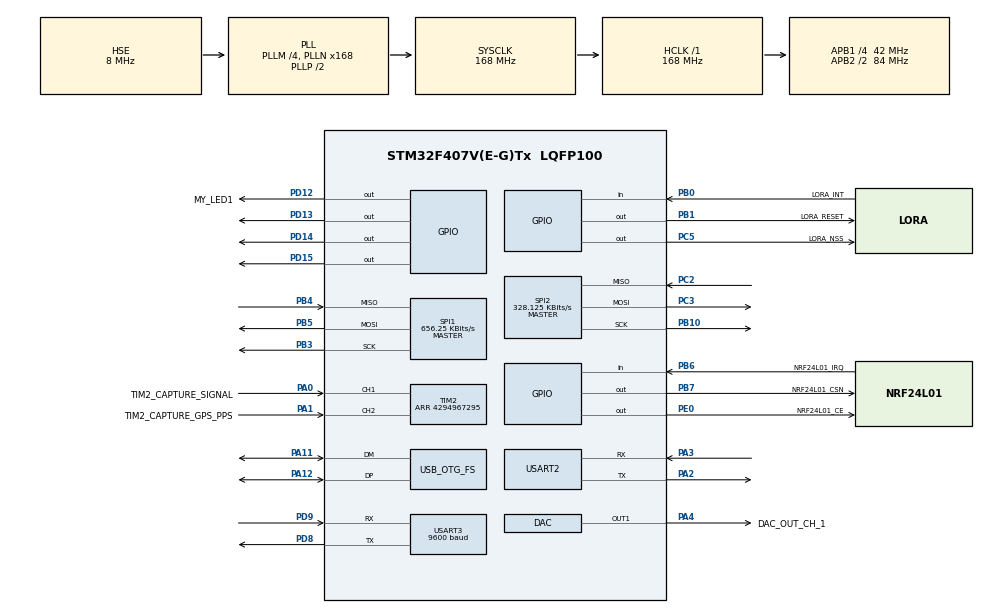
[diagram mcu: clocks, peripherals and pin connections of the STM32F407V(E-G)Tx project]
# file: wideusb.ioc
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DAC.DAC_OutputBuffer=DAC_OUTPUTBUFFER_ENABLE
DAC.DAC_Trigger=DAC_TRIGGER_T4_TRGO
Dma.DAC1.0.Direction=DMA_MEMORY_TO_PERIPH
Dma.DAC1.0.FIFOMode=DMA_FIFOMODE_DISABLE
Dma.DAC1.0.Instance=DMA1_Stream5
Dma.DAC1.0.MemDataAlignment=DMA_MDATAALIGN_HALFWORD
Dma.DAC1.0.MemInc=DMA_MINC_ENABLE
Dma.DAC1.0.Mode=DMA_NORMAL
Dma.DAC1.0.PeriphDataAlignment=DMA_PDATAALIGN_HALFWORD
Dma.DAC1.0.PeriphInc=DMA_PINC_DISABLE
Dma.DAC1.0.Priority=DMA_PRIORITY_LOW
Dma.Request0=DAC1
FREERTOS.HEAP_NUMBER=3
FREERTOS.Tasks01=defaultTask,0,1024,StartDefaultTask,Default,NULL,Dynamic,NULL,NULL
Mcu.Family=STM32F4
Mcu.Name=STM32F407V(E-G)Tx
Mcu.Package=LQFP100
NVIC.DMA1_Stream5_IRQn=true\:5\:0\:false\:false\:true\:true\:false\:true\:true
NVIC.OTG_FS_IRQn=true\:5\:0\:false\:false\:true\:true\:false\:true\:true
NVIC.PriorityGroup=NVIC_PRIORITYGROUP_4
NVIC.TIM2_IRQn=true\:5\:0\:false\:false\:true\:true\:true\:true\:true
NVIC.TIM6_DAC_IRQn=true\:15\:0\:false\:false\:true\:false\:false\:true\:true
NVIC.TimeBase=TIM6_DAC_IRQn
NVIC.TimeBaseIP=TIM6
NVIC.USART3_IRQn=true\:5\:0\:false\:false\:true\:true\:true\:true\:true
PA0-WKUP.GPIO_Label=TIM2_CAPTURE_SIGNAL
PA0-WKUP.Signal=S_TIM2_CH1_ETR
PA1.GPIO_Label=TIM2_CAPTURE_GPS_PPS
PA1.Signal=S_TIM2_CH2
PA11.Mode=Device_Only
PA11.Signal=USB_OTG_FS_DM
PA12.Mode=Device_Only
PA12.Signal=USB_OTG_FS_DP
PA2.Mode=Asynchronous
PA2.Signal=USART2_TX
PA3.Mode=Asynchronous
PA3.Signal=USART2_RX
PA4.GPIO_Label=DAC_OUT_CH_1
PA4.Signal=COMP_DAC1_group
PB0.GPIO_Label=LORA_INT
PB0.Signal=GPIO_Input
PB1.GPIO_Label=LORA_RESET
PB1.Signal=GPIO_Output
PB10.Mode=Full_Duplex_Master
PB10.Signal=SPI2_SCK
PB3.Mode=Full_Duplex_Master
PB3.Signal=SPI1_SCK
PB4.Mode=Full_Duplex_Master
PB4.Signal=SPI1_MISO
PB5.Mode=Full_Duplex_Master
PB5.Signal=SPI1_MOSI
PB6.GPIO_Label=NRF24L01_IRQ
PB6.Signal=GPIO_Input
PB7.GPIO_Label=NRF24L01_CSN
PB7.Signal=GPIO_Output
PC2.Mode=Full_Duplex_Master
PC2.Signal=SPI2_MISO
PC3.Mode=Full_Duplex_Master
PC3.Signal=SPI2_MOSI
PC5.GPIO_Label=LORA_NSS
PC5.Signal=GPIO_Output
PD12.GPIO_Label=MY_LED1
PD12.PinState=GPIO_PIN_RESET
PD12.Signal=GPIO_Output
PD13.Signal=GPIO_Output
PD14.Signal=GPIO_Output
PD15.Signal=GPIO_Output
PD8.Mode=Asynchronous
PD8.Signal=USART3_TX
PD9.Mode=Asynchronous
PD9.Signal=USART3_RX
PE0.GPIO_Label=NRF24L01_CE
PE0.Signal=GPIO_Output
PH0-OSC_IN.Mode=HSE-External-Oscillator
PH0-OSC_IN.Signal=RCC_OSC_IN
PH1-OSC_OUT.Mode=HSE-External-Oscillator
PH1-OSC_OUT.Signal=RCC_OSC_OUT
ProjectManager.HeapSize=0x200
ProjectManager.StackSize=0x400
ProjectManager.TargetToolchain=Makefile
RCC.48MHZClocksFreq_Value=48000000
RCC.AHBFreq_Value=168000000
RCC.APB1CLKDivider=RCC_HCLK_DIV4
RCC.APB1Freq_Value=42000000
RCC.APB1TimFreq_Value=84000000
RCC.APB2CLKDivider=RCC_HCLK_DIV2
RCC.APB2Freq_Value=84000000
RCC.APB2TimFreq_Value=168000000
RCC.CortexFreq_Value=168000000
RCC.HCLKFreq_Value=168000000
RCC.HSE_VALUE=8000000
RCC.HSI_VALUE=16000000
RCC.LSE_VALUE=32768
RCC.PLLM=4
RCC.PLLN=168
RCC.PLLQ=7
RCC.SYSCLKFreq_VALUE=168000000
RCC.SYSCLKSource=RCC_SYSCLKSOURCE_PLLCLK
RCC.VCOOutputFreq_Value=336000000
SH.COMP_DAC1_group.0=DAC_OUT1,DAC_OUT1
SH.S_TIM2_CH1_ETR.0=TIM2_CH1,Input_Capture1_from_TI1
SH.S_TIM2_CH2.0=TIM2_CH2,Input_Capture2_from_TI2
SPI1.BaudRatePrescaler=SPI_BAUDRATEPRESCALER_128
SPI1.CalculateBaudRate=656.25 KBits/s
SPI1.Direction=SPI_DIRECTION_2LINES
SPI1.Mode=SPI_MODE_MASTER
SPI1.VirtualType=VM_MASTER
SPI2.BaudRatePrescaler=SPI_BAUDRATEPRESCALER_128
SPI2.CalculateBaudRate=328.125 KBits/s
SPI2.Direction=SPI_DIRECTION_2LINES
SPI2.Mode=SPI_MODE_MASTER
SPI2.VirtualType=VM_MASTER
TIM2.Channel-Input_Capture1_from_TI1=TIM_CHANNEL_1
TIM2.Channel-Input_Capture2_from_TI2=TIM_CHANNEL_2
TIM2.Period=4294967295
TIM4.Period=50
TIM4.Prescaler=20
TIM4.TIM_MasterOutputTrigger=TIM_TRGO_UPDATE
USART2.VirtualMode=VM_ASYNC
USART3.BaudRate=9600
USART3.Mode=MODE_TX_RX
USART3.OverSampling=UART_OVERSAMPLING_16
USART3.StopBits=STOPBITS_1
USART3.VirtualMode=VM_ASYNC
USB_DEVICE.APP_RX_DATA_SIZE-CDC_FS=1024
USB_DEVICE.CLASS_NAME_FS=CDC
USB_DEVICE.MANUFACTURER_STRING-CDC_FS=WideUSB Project
USB_DEVICE.PRODUCT_STRING_CDC_FS=WideUSB Virtual ComPort
USB_DEVICE.VirtualMode-CDC_FS=Cdc
USB_DEVICE.VirtualModeFS=Cdc_FS
USB_OTG_FS.VirtualMode=Device_Only
VP_FREERTOS_VS_CMSIS_V1.Mode=CMSIS_V1
VP_SYS_VS_tim6.Mode=TIM6
VP_TIM2_VS_ClockSourceINT.Mode=Internal
VP_TIM4_VS_ClockSourceINT.Mode=Internal
VP_USB_DEVICE_VS_USB_DEVICE_CDC_FS.Mode=CDC_FS
board=custom

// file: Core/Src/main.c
/* USER CODE BEGIN Header */
/**
  ******************************************************************************
  * @file           : main.c
  * @brief          : Main program body
  ******************************************************************************
  ** This notice applies to any and all portions of this file
  * that are not between comment pairs USER CODE BEGIN and
  * USER CODE END. Other portions of this file, whether
  * inserted by the user or by software development tools
  * are owned by their respective copyright owners.
  *
  * COPYRIGHT(c) 2020 STMicroelectronics
  *
  * Redistribution and use in source and binary forms, with or without modification,
  * are permitted provided that the following conditions are met:
  *   1. Redistributions of source code must retain the above copyright notice,
  *      this list of conditions and the following disclaimer.
  *   2. Redistributions in binary form must reproduce the above copyright notice,
  *      this list of conditions and the following disclaimer in the documentation
  *      and/or other materials provided with the distribution.
  *   3. Neither the name of STMicroelectronics nor the names of its contributors
  *      may be used to endorse or promote products derived from this software
  *      without specific prior written permission.
  *
  * THIS SOFTWARE IS PROVIDED BY THE COPYRIGHT HOLDERS AND CONTRIBUTORS "AS IS"
  * AND ANY EXPRESS OR IMPLIED WARRANTIES, INCLUDING, BUT NOT LIMITED TO, THE
  * IMPLIED WARRANTIES OF MERCHANTABILITY AND FITNESS FOR A PARTICULAR PURPOSE ARE
  * DISCLAIMED. IN NO EVENT SHALL THE COPYRIGHT HOLDER OR CONTRIBUTORS BE LIABLE
  * FOR ANY DIRECT, INDIRECT, INCIDENTAL, SPECIAL, EXEMPLARY, OR CONSEQUENTIAL
  * DAMAGES (INCLUDING, BUT NOT LIMITED TO, PROCUREMENT OF SUBSTITUTE GOODS OR
  * SERVICES; LOSS OF USE, DATA, OR PROFITS; OR BUSINESS INTERRUPTION) HOWEVER
  * CAUSED AND ON ANY THEORY OF LIABILITY, WHETHER IN CONTRACT, STRICT LIABILITY,
  * OR TORT (INCLUDING NEGLIGENCE OR OTHERWISE) ARISING IN ANY WAY OUT OF THE USE
  * OF THIS SOFTWARE, EVEN IF ADVISED OF THE POSSIBILITY OF SUCH DAMAGE.
  *
  ******************************************************************************
  */
/* USER CODE END Header */
#include "main.h"
#include "cmsis_os.h"
#include "dac.h"
#include "dma.h"
#include "spi.h"
#include "tim.h"
#include "usart.h"
#include "usb_device.h"
#include "gpio.h"

void SystemClock_Config(void);
void MX_FREERTOS_Init(void);

int main(void)
{

  /* MCU Configuration--------------------------------------------------------*/

  /* Reset of all peripherals, Initializes the Flash interface and the Systick. */
  HAL_Init();

  /* Configure the system clock */
  SystemClock_Config();

  /* Initialize all configured peripherals */
  MX_GPIO_Init();
  MX_DMA_Init();
  MX_USART3_UART_Init();
  MX_TIM2_Init();
  MX_DAC_Init();
  MX_TIM4_Init();
  MX_SPI1_Init();
  MX_SPI2_Init();
  MX_USART2_UART_Init();
  /* USER CODE BEGIN 2 */
  //HAL_TIM_Base_Start(&htim4);
  //fill_dac_buffer();
  //run_dac();
    /*while(1)
    {
    }*/
  /*while (1)
  {
      if (ready)
      {
          ready = 0;
            //run_dac();
          //run_dac();
      }
  }*/

  /* USER CODE END 2 */

  /* Call init function for freertos objects (in freertos.c) */
  MX_FREERTOS_Init();

  /* Start scheduler */
  osKernelStart();

  /* We should never get here as control is now taken by the scheduler */
  /* Infinite loop */
  while (1)
  {

  }
}

void SystemClock_Config(void)
{
  RCC_OscInitTypeDef RCC_OscInitStruct = {0};
  RCC_ClkInitTypeDef RCC_ClkInitStruct = {0};

  /** Configure the main internal regulator output voltage
  */
  __HAL_RCC_PWR_CLK_ENABLE();
  __HAL_PWR_VOLTAGESCALING_CONFIG(PWR_REGULATOR_VOLTAGE_SCALE1);

  /** Initializes the RCC Oscillators according to the specified parameters
  * in the RCC_OscInitTypeDef structure.
  */
  RCC_OscInitStruct.OscillatorType = RCC_OSCILLATORTYPE_HSE;
  RCC_OscInitStruct.HSEState = RCC_HSE_ON;
  RCC_OscInitStruct.PLL.PLLState = RCC_PLL_ON;
  RCC_OscInitStruct.PLL.PLLSource = RCC_PLLSOURCE_HSE;
  RCC_OscInitStruct.PLL.PLLM = 4;
  RCC_OscInitStruct.PLL.PLLN = 168;
  RCC_OscInitStruct.PLL.PLLP = RCC_PLLP_DIV2;
  RCC_OscInitStruct.PLL.PLLQ = 7;
  if (HAL_RCC_OscConfig(&RCC_OscInitStruct) != HAL_OK)
  {
    Error_Handler();
  }

  /** Initializes the CPU, AHB and APB buses clocks
  */
  RCC_ClkInitStruct.ClockType = RCC_CLOCKTYPE_HCLK|RCC_CLOCKTYPE_SYSCLK
                              |RCC_CLOCKTYPE_PCLK1|RCC_CLOCKTYPE_PCLK2;
  RCC_ClkInitStruct.SYSCLKSource = RCC_SYSCLKSOURCE_PLLCLK;
  RCC_ClkInitStruct.AHBCLKDivider = RCC_SYSCLK_DIV1;
  RCC_ClkInitStruct.APB1CLKDivider = RCC_HCLK_DIV4;
  RCC_ClkInitStruct.APB2CLKDivider = RCC_HCLK_DIV2;

  if (HAL_RCC_ClockConfig(&RCC_ClkInitStruct, FLASH_LATENCY_5) != HAL_OK)
  {
    Error_Handler();
  }
}

void HAL_TIM_PeriodElapsedCallback(TIM_HandleTypeDef *htim)
{
  if (htim->Instance == TIM6) {
    HAL_IncTick();
  }
}

void Error_Handler(void)
{
  /* USER CODE BEGIN Error_Handler_Debug */
  /* User can add his own implementation to report the HAL error return state */
    printf("Error_Handler(void) called\r\n");
  /* USER CODE END Error_Handler_Debug */
}

#ifdef  USE_FULL_ASSERT
/**
  * @brief  Reports the name of the source file and the source line number
  *         where the assert_param error has occurred.
  * @param  file: pointer to the source file name
  * @param  line: assert_param error line source number
  * @retval None
  */
void assert_failed(uint8_t *file, uint32_t line)
{
  /* USER CODE BEGIN 6 */
  /* User can add his own implementation to report the file name and line number,
     tex: printf("Wrong parameters value: file %s on line %d\r\n", file, line) */
    HAL_GPIO_WritePin(GPIOD, GPIO_PIN_14, GPIO_PIN_SET);
    // Ok, good enough
    printf("Wrong parameters value: file %s on line %ld\r\n", file, line);
  /* USER CODE END 6 */
}
#endif /* USE_FULL_ASSERT */

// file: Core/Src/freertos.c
/* USER CODE BEGIN Header */
/**
  ******************************************************************************
  * File Name          : freertos.c
  * Description        : Code for freertos applications
  ******************************************************************************
  * This notice applies to any and all portions of this file
  * that are not between comment pairs USER CODE BEGIN and
  * USER CODE END. Other portions of this file, whether
  * inserted by the user or by software development tools
  * are owned by their respective copyright owners.
  *
  * Copyright (c) 2020 STMicroelectronics International N.V.
  * All rights reserved.
  *
  * Redistribution and use in source and binary forms, with or without
  * modification, are permitted, provided that the following conditions are met:
  *
  * 1. Redistribution of source code must retain the above copyright notice,
  *    this list of conditions and the following disclaimer.
  * 2. Redistributions in binary form must reproduce the above copyright notice,
  *    this list of conditions and the following disclaimer in the documentation
  *    and/or other materials provided with the distribution.
  * 3. Neither the name of STMicroelectronics nor the names of other
  *    contributors to this software may be used to endorse or promote products
  *    derived from this software without specific written permission.
  * 4. This software, including modifications and/or derivative works of this
  *    software, must execute solely and exclusively on microcontroller or
  *    microprocessor devices manufactured by or for STMicroelectronics.
  * 5. Redistribution and use of this software other than as permitted under
  *    this license is void and will automatically terminate your rights under
  *    this license.
  *
  * THIS SOFTWARE IS PROVIDED BY STMICROELECTRONICS AND CONTRIBUTORS "AS IS"
  * AND ANY EXPRESS, IMPLIED OR STATUTORY WARRANTIES, INCLUDING, BUT NOT
  * LIMITED TO, THE IMPLIED WARRANTIES OF MERCHANTABILITY, FITNESS FOR A
  * PARTICULAR PURPOSE AND NON-INFRINGEMENT OF THIRD PARTY INTELLECTUAL PROPERTY
  * RIGHTS ARE DISCLAIMED TO THE FULLEST EXTENT PERMITTED BY LAW. IN NO EVENT
  * SHALL STMICROELECTRONICS OR CONTRIBUTORS BE LIABLE FOR ANY DIRECT, INDIRECT,
  * INCIDENTAL, SPECIAL, EXEMPLARY, OR CONSEQUENTIAL DAMAGES (INCLUDING, BUT NOT
  * LIMITED TO, PROCUREMENT OF SUBSTITUTE GOODS OR SERVICES; LOSS OF USE, DATA,
  * OR PROFITS; OR BUSINESS INTERRUPTION) HOWEVER CAUSED AND ON ANY THEORY OF
  * LIABILITY, WHETHER IN CONTRACT, STRICT LIABILITY, OR TORT (INCLUDING
  * NEGLIGENCE OR OTHERWISE) ARISING IN ANY WAY OUT OF THE USE OF THIS SOFTWARE,
  * EVEN IF ADVISED OF THE POSSIBILITY OF SUCH DAMAGE.
  *
  ******************************************************************************
  */
/* USER CODE END Header */

#include "FreeRTOS.h"
#include "task.h"
#include "main.h"
#include "cmsis_os.h"

/* USER CODE BEGIN Includes */
#include "cpp-bootstrap.h"
/* USER CODE END Includes */

osThreadId defaultTaskHandle;

void StartDefaultTask(void const * argument);

extern void MX_USB_DEVICE_Init(void);
void MX_FREERTOS_Init(void); /* (MISRA C 2004 rule 8.1) */

/* GetIdleTaskMemory prototype (linked to static allocation support) */
void vApplicationGetIdleTaskMemory( StaticTask_t **ppxIdleTaskTCBBuffer, StackType_t **ppxIdleTaskStackBuffer, uint32_t *pulIdleTaskStackSize );

/* USER CODE BEGIN GET_IDLE_TASK_MEMORY */
static StaticTask_t xIdleTaskTCBBuffer;
static StackType_t xIdleStack[configMINIMAL_STACK_SIZE];

void vApplicationGetIdleTaskMemory( StaticTask_t **ppxIdleTaskTCBBuffer, StackType_t **ppxIdleTaskStackBuffer, uint32_t *pulIdleTaskStackSize )
{
  *ppxIdleTaskTCBBuffer = &xIdleTaskTCBBuffer;
  *ppxIdleTaskStackBuffer = &xIdleStack[0];
  *pulIdleTaskStackSize = configMINIMAL_STACK_SIZE;
  /* place for user code */
}
/* USER CODE END GET_IDLE_TASK_MEMORY */

void MX_FREERTOS_Init(void) {

  /* Create the thread(s) */
  /* definition and creation of defaultTask */
  osThreadDef(defaultTask, StartDefaultTask, osPriorityNormal, 0, 1024);
  defaultTaskHandle = osThreadCreate(osThread(defaultTask), NULL);

}

void StartDefaultTask(void const * argument)
{
  /* init code for USB_DEVICE */
  MX_USB_DEVICE_Init();
  /* USER CODE BEGIN StartDefaultTask */
  /* Infinite loop */
  (void) argument;
  cpp_bootstrap();

  for(;;)
  {
    osDelay(1);
  }
  /* USER CODE END StartDefaultTask */
}
